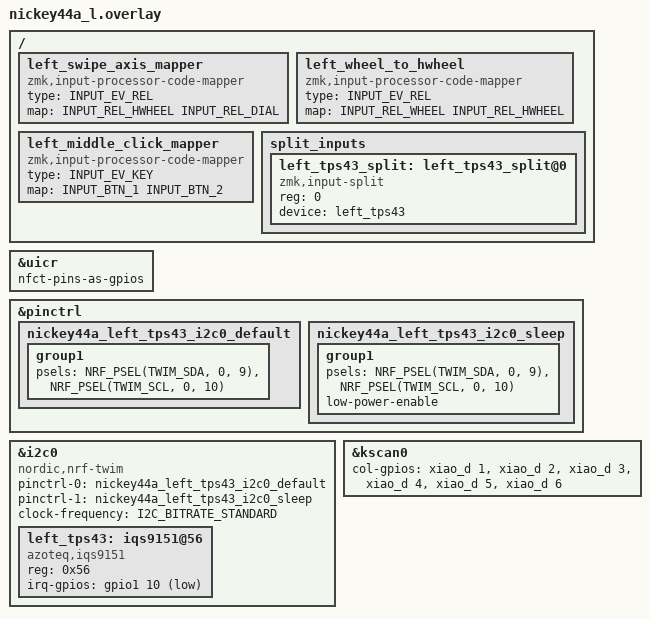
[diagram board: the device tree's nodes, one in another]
#include "nickey44a.dtsi"
#include <input/processors.dtsi>
#include <dt-bindings/gpio/gpio.h>
#include <dt-bindings/pinctrl/nrf-pinctrl.h>
#include <zephyr/dt-bindings/input/input-event-codes.h>

/*
 * yuPad43 (IQS9151) wiring:
 *   SDA = XIAO NFC1/P0.09
 *   SCL = XIAO NFC2/P0.10
 *   RDY = XIAO P1.10 (active-low)
 *   RST = not used (driver resets over I2C)
 */

&uicr {
    nfct-pins-as-gpios;
};

&pinctrl {
    nickey44a_left_tps43_i2c0_default: nickey44a_left_tps43_i2c0_default {
        group1 {
            psels = <NRF_PSEL(TWIM_SDA, 0, 9)>,
                    <NRF_PSEL(TWIM_SCL, 0, 10)>;
        };
    };

    nickey44a_left_tps43_i2c0_sleep: nickey44a_left_tps43_i2c0_sleep {
        group1 {
            psels = <NRF_PSEL(TWIM_SDA, 0, 9)>,
                    <NRF_PSEL(TWIM_SCL, 0, 10)>;
            low-power-enable;
        };
    };
};

/ {
    left_swipe_axis_mapper: left_swipe_axis_mapper {
        compatible = "zmk,input-processor-code-mapper";
        #input-processor-cells = <0>;
        type = <INPUT_EV_REL>;
        map = <INPUT_REL_HWHEEL INPUT_REL_DIAL>;
    };

    left_wheel_to_hwheel: left_wheel_to_hwheel {
        compatible = "zmk,input-processor-code-mapper";
        #input-processor-cells = <0>;
        type = <INPUT_EV_REL>;
        map = <INPUT_REL_WHEEL INPUT_REL_HWHEEL>;
    };

    left_middle_click_mapper: left_middle_click_mapper {
        compatible = "zmk,input-processor-code-mapper";
        #input-processor-cells = <0>;
        type = <INPUT_EV_KEY>;
        map = <INPUT_BTN_1 INPUT_BTN_2>;
    };

    split_inputs {
        #address-cells = <1>;
        #size-cells = <0>;

        left_tps43_split: left_tps43_split@0 {
            compatible = "zmk,input-split";
            reg = <0>;
            device = <&left_tps43>;
            /* No remapping: 2-finger tap = right click, 2-finger swipe = scroll. */
        };
    };
};

&i2c0 {
    status = "okay";
    compatible = "nordic,nrf-twim";
    pinctrl-0 = <&nickey44a_left_tps43_i2c0_default>;
    pinctrl-1 = <&nickey44a_left_tps43_i2c0_sleep>;
    pinctrl-names = "default", "sleep";
    clock-frequency = <I2C_BITRATE_STANDARD>;
    #address-cells = <1>;
    #size-cells = <0>;

    left_tps43: iqs9151@56 {
        compatible = "azoteq,iqs9151";
        reg = <0x56>;
        status = "okay";
        irq-gpios = <&gpio1 10 (GPIO_ACTIVE_LOW | GPIO_PULL_UP)>;
    };
};

&kscan0 {
        col-gpios
            = <&xiao_d 1 GPIO_ACTIVE_HIGH>
            , <&xiao_d 2 GPIO_ACTIVE_HIGH>
            , <&xiao_d 3 GPIO_ACTIVE_HIGH>
            , <&xiao_d 4 GPIO_ACTIVE_HIGH>
            , <&xiao_d 5 GPIO_ACTIVE_HIGH>
            , <&xiao_d 6 GPIO_ACTIVE_HIGH>
            ;
};
